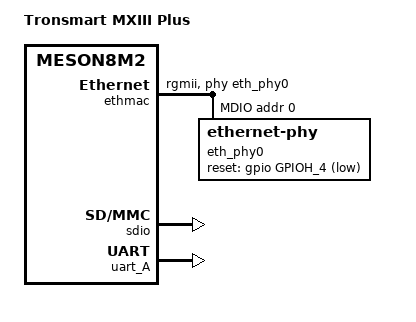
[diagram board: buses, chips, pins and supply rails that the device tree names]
// SPDX-License-Identifier: (GPL-2.0+ OR MIT)
/*
 * Copyright (c) 2018 Oleg Ivanov <balbes-150@yandex.ru>
 * Copyright (c) 2018 Martin Blumenstingl <martin.blumenstingl@googlemail.com>
 */

/dts-v1/;

#include "meson8m2-mxiii.dtsi"

/ {
	model = "Tronsmart MXIII Plus";
	compatible = "tronsmart,mxiii-plus", "amlogic,meson8m2";

	aliases {
		serial1 = &uart_A;
	};
};

&ethmac {
	status = "okay";

	pinctrl-0 = <&eth_rgmii_pins>;
	pinctrl-names = "default";

	phy-handle = <&eth_phy0>;
	phy-mode = "rgmii";

	amlogic,tx-delay-ns = <2>;

	mdio {
		compatible = "snps,dwmac-mdio";
		#address-cells = <1>;
		#size-cells = <0>;

		eth_phy0: ethernet-phy@0 {
			/* Realtek RTL8211F (0x001cc916) */
			reg = <0>;

			reset-assert-us = <10000>;
			reset-deassert-us = <30000>;
			reset-gpios = <&gpio GPIOH_4 GPIO_ACTIVE_LOW>;
		};
	};
};

&sdio {
	status = "okay";

	pinctrl-0 = <&sd_b_pins>;
	pinctrl-names = "default";

	/* SD card */
	sd_card_slot: slot@1 {
		compatible = "mmc-slot";
		reg = <1>;
		status = "okay";

		bus-width = <4>;
		no-sdio;
		cap-mmc-highspeed;
		cap-sd-highspeed;
		disable-wp;

		cd-gpios = <&gpio CARD_6 GPIO_ACTIVE_LOW>;

		vmmc-supply = <&vcc_3v3>;
	};
};

&uart_A {
	status = "okay";
	pinctrl-0 = <&uart_a1_pins>, <&uart_a1_cts_rts_pins>;
	pinctrl-names = "default";
	uart-has-rtscts;
};
